AUTOSAR XML (schema 00049)
package /SR_Comopsition_Lab
  sender receiver interface SRI_LightControl
    data LightControl: type=uint32
  sender receiver interface SRI_LightActuate
    data LightActuate: type=uint32
  sensor actuator sw component type LightControlStatus_SWC
    provide port Pp_SR_LightControl: provided-interface=SRI_LightControl
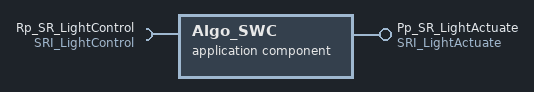
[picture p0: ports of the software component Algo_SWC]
  application sw component type Algo_SWC
    require port Rp_SR_LightControl: required-interface=SRI_LightControl
    provide port Pp_SR_LightActuate: provided-interface=SRI_LightActuate
  sensor actuator sw component type LightActuate_SWC
    require port Pp_SR_LightControl: required-interface=SRI_LightActuate
  composition sw component type SW_Composite1
    provide port Pp_SR_LightActuate_Composite: provided-interface=SRI_LightActuate
    component LC_SA_SWC1: type=LightControlStatus_SWC
    component LA_SWC2: type=Algo_SWC
    connect LC_SA_SWC1.Pp_SR_LightControl -> LA_SWC2.Rp_SR_LightControl
    delegate LA_SWC2.Pp_SR_LightActuate <-> outer port Pp_SR_LightActuate_Composite
  composition sw component type TopLevel_CompositeSWC
    component SW_Composite1_instant: type=SW_Composite1
    component LightActuate_SWC3: type=LightActuate_SWC
    connect SW_Composite1_instant.Pp_SR_LightActuate_Composite -> LightActuate_SWC3.Pp_SR_LightControl
